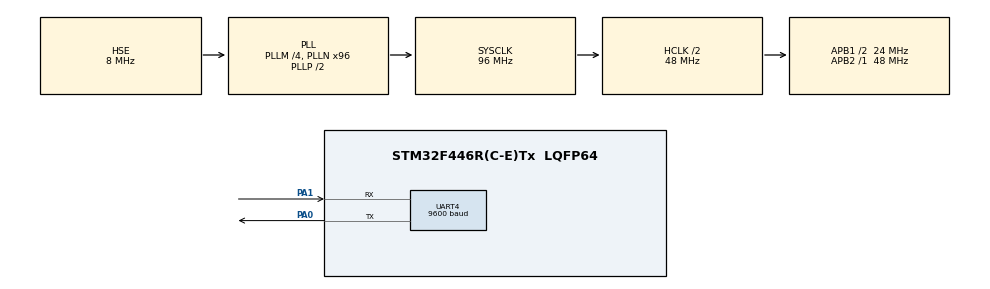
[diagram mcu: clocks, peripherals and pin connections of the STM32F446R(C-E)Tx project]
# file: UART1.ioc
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Mcu.Family=STM32F4
Mcu.Name=STM32F446R(C-E)Tx
Mcu.Package=LQFP64
NVIC.PriorityGroup=NVIC_PRIORITYGROUP_0
NVIC.UART4_IRQn=true\:0\:0\:false\:false\:true\:true\:true\:true
PA0-WKUP.GPIO_PuPd=GPIO_NOPULL
PA0-WKUP.GPIO_Speed=GPIO_SPEED_FREQ_MEDIUM
PA0-WKUP.Mode=Asynchronous
PA0-WKUP.Signal=UART4_TX
PA1.GPIO_PuPd=GPIO_NOPULL
PA1.GPIO_Speed=GPIO_SPEED_FREQ_MEDIUM
PA1.Mode=Asynchronous
PA1.Signal=UART4_RX
PH0-OSC_IN.Mode=HSE-External-Oscillator
PH0-OSC_IN.Signal=RCC_OSC_IN
PH1-OSC_OUT.Mode=HSE-External-Oscillator
PH1-OSC_OUT.Signal=RCC_OSC_OUT
ProjectManager.HeapSize=0x200
ProjectManager.StackSize=0x400
ProjectManager.TargetToolchain=STM32CubeIDE
RCC.AHBCLKDivider=RCC_SYSCLK_DIV2
RCC.AHBFreq_Value=48000000
RCC.APB1CLKDivider=RCC_HCLK_DIV2
RCC.APB1Freq_Value=24000000
RCC.APB1TimFreq_Value=48000000
RCC.APB2Freq_Value=48000000
RCC.APB2TimFreq_Value=48000000
RCC.CortexFreq_Value=48000000
RCC.FLatency-AdvancedSettings=FLASH_LATENCY_1
RCC.HCLKFreq_Value=48000000
RCC.HSE_VALUE=8000000
RCC.HSI_VALUE=16000000
RCC.LSE_VALUE=32768
RCC.PLLM=4
RCC.PLLN=96
RCC.PLLSourceVirtual=RCC_PLLSOURCE_HSE
RCC.SYSCLKFreq_VALUE=96000000
RCC.SYSCLKSource=RCC_SYSCLKSOURCE_PLLCLK
RCC.USBFreq_Value=96000000
RCC.VCOOutputFreq_Value=192000000
UART4.BaudRate=9600
UART4.VirtualMode=Asynchronous
board=NUCLEO-F446RE

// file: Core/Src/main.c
/* USER CODE BEGIN Header */
/**
  ******************************************************************************
  * @file           : main.c
  * @brief          : Main program body
  ******************************************************************************
  * @attention
  *
  * Copyright (c) 2024 STMicroelectronics.
  * All rights reserved.
  *
  * This software is licensed under terms that can be found in the LICENSE file
  * in the root directory of this software component.
  * If no LICENSE file comes with this software, it is provided AS-IS.
  *
  ******************************************************************************
  */
/* USER CODE END Header */
#include "main.h"

UART_HandleTypeDef huart4;

/* USER CODE BEGIN PV */
uint8_t buffer[10];
uint8_t senddata[4] = {0x66, 0x42, 0x00, 0xA8};
uint8_t trame[10];

uint8_t rxData = 0;
/* USER CODE END PV */

void SystemClock_Config(void);
static void MX_GPIO_Init(void);
static void MX_UART4_Init(void);

/* USER CODE BEGIN 0 */
void HAL_UART_RxCpltCallback(UART_HandleTypeDef *huart)
  {
	 //receiveUart();

	HAL_UART_Receive_IT(&huart4,buffer, 10);//sizeof(buffer));

}

void sendParameter()

{

  HAL_UART_Transmit_IT(&huart4, senddata, 4);

   HAL_Delay(40);

}

/* USER CODE END 0 */

int main(void)
{

  /* MCU Configuration--------------------------------------------------------*/

  /* Reset of all peripherals, Initializes the Flash interface and the Systick. */
  HAL_Init();

  /* Configure the system clock */
  SystemClock_Config();

  /* Initialize all configured peripherals */
  MX_GPIO_Init();
  MX_UART4_Init();
  /* USER CODE BEGIN 2 */
  //HAL_UART_MspInit(&huart2);

 HAL_UART_Receive_IT(&huart4,buffer, 10);//sizeof(buffer));

  /* USER CODE END 2 */

  /* Infinite loop */
  while (1)
  {

    /* USER CODE BEGIN 3 */
	 sendParameter();
  }
  /* USER CODE END 3 */
}

void SystemClock_Config(void)
{
  RCC_OscInitTypeDef RCC_OscInitStruct = {0};
  RCC_ClkInitTypeDef RCC_ClkInitStruct = {0};

  /** Configure the main internal regulator output voltage
  */
  __HAL_RCC_PWR_CLK_ENABLE();
  __HAL_PWR_VOLTAGESCALING_CONFIG(PWR_REGULATOR_VOLTAGE_SCALE3);

  /** Initializes the RCC Oscillators according to the specified parameters
  * in the RCC_OscInitTypeDef structure.
  */
  RCC_OscInitStruct.OscillatorType = RCC_OSCILLATORTYPE_HSE;
  RCC_OscInitStruct.HSEState = RCC_HSE_ON;
  RCC_OscInitStruct.PLL.PLLState = RCC_PLL_ON;
  RCC_OscInitStruct.PLL.PLLSource = RCC_PLLSOURCE_HSE;
  RCC_OscInitStruct.PLL.PLLM = 4;
  RCC_OscInitStruct.PLL.PLLN = 96;
  RCC_OscInitStruct.PLL.PLLP = RCC_PLLP_DIV2;
  RCC_OscInitStruct.PLL.PLLQ = 2;
  RCC_OscInitStruct.PLL.PLLR = 2;
  if (HAL_RCC_OscConfig(&RCC_OscInitStruct) != HAL_OK)
  {
    Error_Handler();
  }

  /** Initializes the CPU, AHB and APB buses clocks
  */
  RCC_ClkInitStruct.ClockType = RCC_CLOCKTYPE_HCLK|RCC_CLOCKTYPE_SYSCLK
                              |RCC_CLOCKTYPE_PCLK1|RCC_CLOCKTYPE_PCLK2;
  RCC_ClkInitStruct.SYSCLKSource = RCC_SYSCLKSOURCE_PLLCLK;
  RCC_ClkInitStruct.AHBCLKDivider = RCC_SYSCLK_DIV2;
  RCC_ClkInitStruct.APB1CLKDivider = RCC_HCLK_DIV2;
  RCC_ClkInitStruct.APB2CLKDivider = RCC_HCLK_DIV1;

  if (HAL_RCC_ClockConfig(&RCC_ClkInitStruct, FLASH_LATENCY_1) != HAL_OK)
  {
    Error_Handler();
  }
}

static void MX_UART4_Init(void)
{

  huart4.Instance = UART4;
  huart4.Init.BaudRate = 9600;
  huart4.Init.WordLength = UART_WORDLENGTH_8B;
  huart4.Init.StopBits = UART_STOPBITS_1;
  huart4.Init.Parity = UART_PARITY_NONE;
  huart4.Init.Mode = UART_MODE_TX_RX;
  huart4.Init.HwFlowCtl = UART_HWCONTROL_NONE;
  huart4.Init.OverSampling = UART_OVERSAMPLING_16;
  if (HAL_UART_Init(&huart4) != HAL_OK)
  {
    Error_Handler();
  }

}

static void MX_GPIO_Init(void)
{

  /* GPIO Ports Clock Enable */
  __HAL_RCC_GPIOH_CLK_ENABLE();
  __HAL_RCC_GPIOA_CLK_ENABLE();

}

void Error_Handler(void)
{
  __disable_irq();
  while (1)
  {
  }
}
